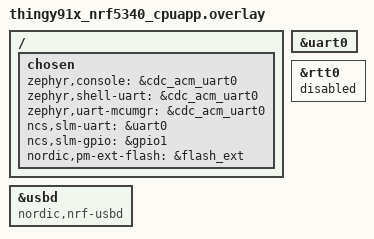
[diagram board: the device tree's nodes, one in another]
/* Copyright (c) 2024 Nordic Semiconductor ASA
 *
 * SPDX-License-Identifier: LicenseRef-Nordic-5-Clause
 */

#include <thingy91x_nrf53_wifi.dtsi>

&usbd {
	compatible = "nordic,nrf-usbd";
	status = "okay";
};

/ {
	chosen {
        zephyr,console = &cdc_acm_uart0;
		zephyr,shell-uart = &cdc_acm_uart0;
		zephyr,uart-mcumgr = &cdc_acm_uart0;
		ncs,slm-uart = &uart0;
		ncs,slm-gpio = &gpio1;
        nordic,pm-ext-flash = &flash_ext;
	};
};

&uart0 {
	status = "okay";
};

&rtt0 {
	status = "disabled";
};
